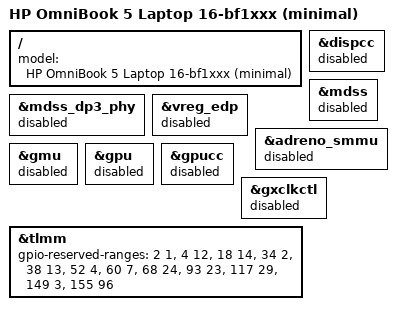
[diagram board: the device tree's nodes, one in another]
// SPDX-License-Identifier: BSD-3-Clause
/*
 * HP OmniBook 5 16-bf1xxx, minimal device tree: the daily device tree with
 * the native display and the GPU left out, so the firmware framebuffer
 * stays lit. The fallback when the display or the GPU does not come up.
 * USB and the EC stay on, so a kernel can still be installed from the
 * USB stick.
 */
/dts-v1/;

#include "mahua-hp-omnibook-5-bf1xxx.dts"

/ {
	model = "HP OmniBook 5 Laptop 16-bf1xxx (minimal)";
};

/*
 * Leave the display to the firmware framebuffer. The display clock
 * controller reprograms its PLLs at probe and, with no MDSS consumer,
 * its sync_state would power off the MDSS GDSC; pd_ignore_unused does
 * not cover that path.
 */
&dispcc {
	status = "disabled";
};

&mdss {
	status = "disabled";
};

&mdss_dp3_phy {
	status = "disabled";
};

&vreg_edp {
	status = "disabled";
};

&adreno_smmu {
	status = "disabled";
};

&gmu {
	status = "disabled";
};

&gpu {
	status = "disabled";
};

&gpucc {
	status = "disabled";
};

&gxclkctl {
	status = "disabled";
};

&tlmm {
	/*
	 * The daily allow-list with the eDP pins 18, 70 and 119 reserved: the
	 * firmware drives them and nothing in this tree does.
	 */
	gpio-reserved-ranges = <2 1>, <4 12>, <18 14>, <34 2>, <38 13>,
			       <52 4>, <60 7>, <68 24>, <93 23>, <117 29>,
			       <149 3>, <155 96>;
};
